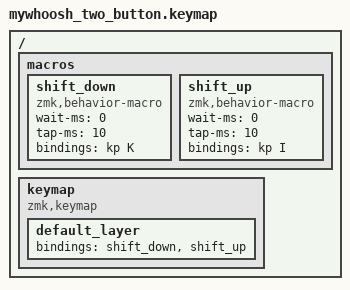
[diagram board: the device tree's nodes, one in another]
#include <behaviors.dtsi>
#include <dt-bindings/zmk/keys.h>

/ {
    macros {
        shift_down: shift_down {
            compatible = "zmk,behavior-macro";
            #binding-cells = <0>;
            wait-ms = <0>;
            tap-ms = <10>;
            bindings = <&kp K>;
        };

        shift_up: shift_up {
            compatible = "zmk,behavior-macro";
            #binding-cells = <0>;
            wait-ms = <0>;
            tap-ms = <10>;
            bindings = <&kp I>;
        };
    };

    keymap {
        compatible = "zmk,keymap";

        default_layer {
            bindings = <
                &shift_down
                &shift_up
            >;
        };
    };
};
